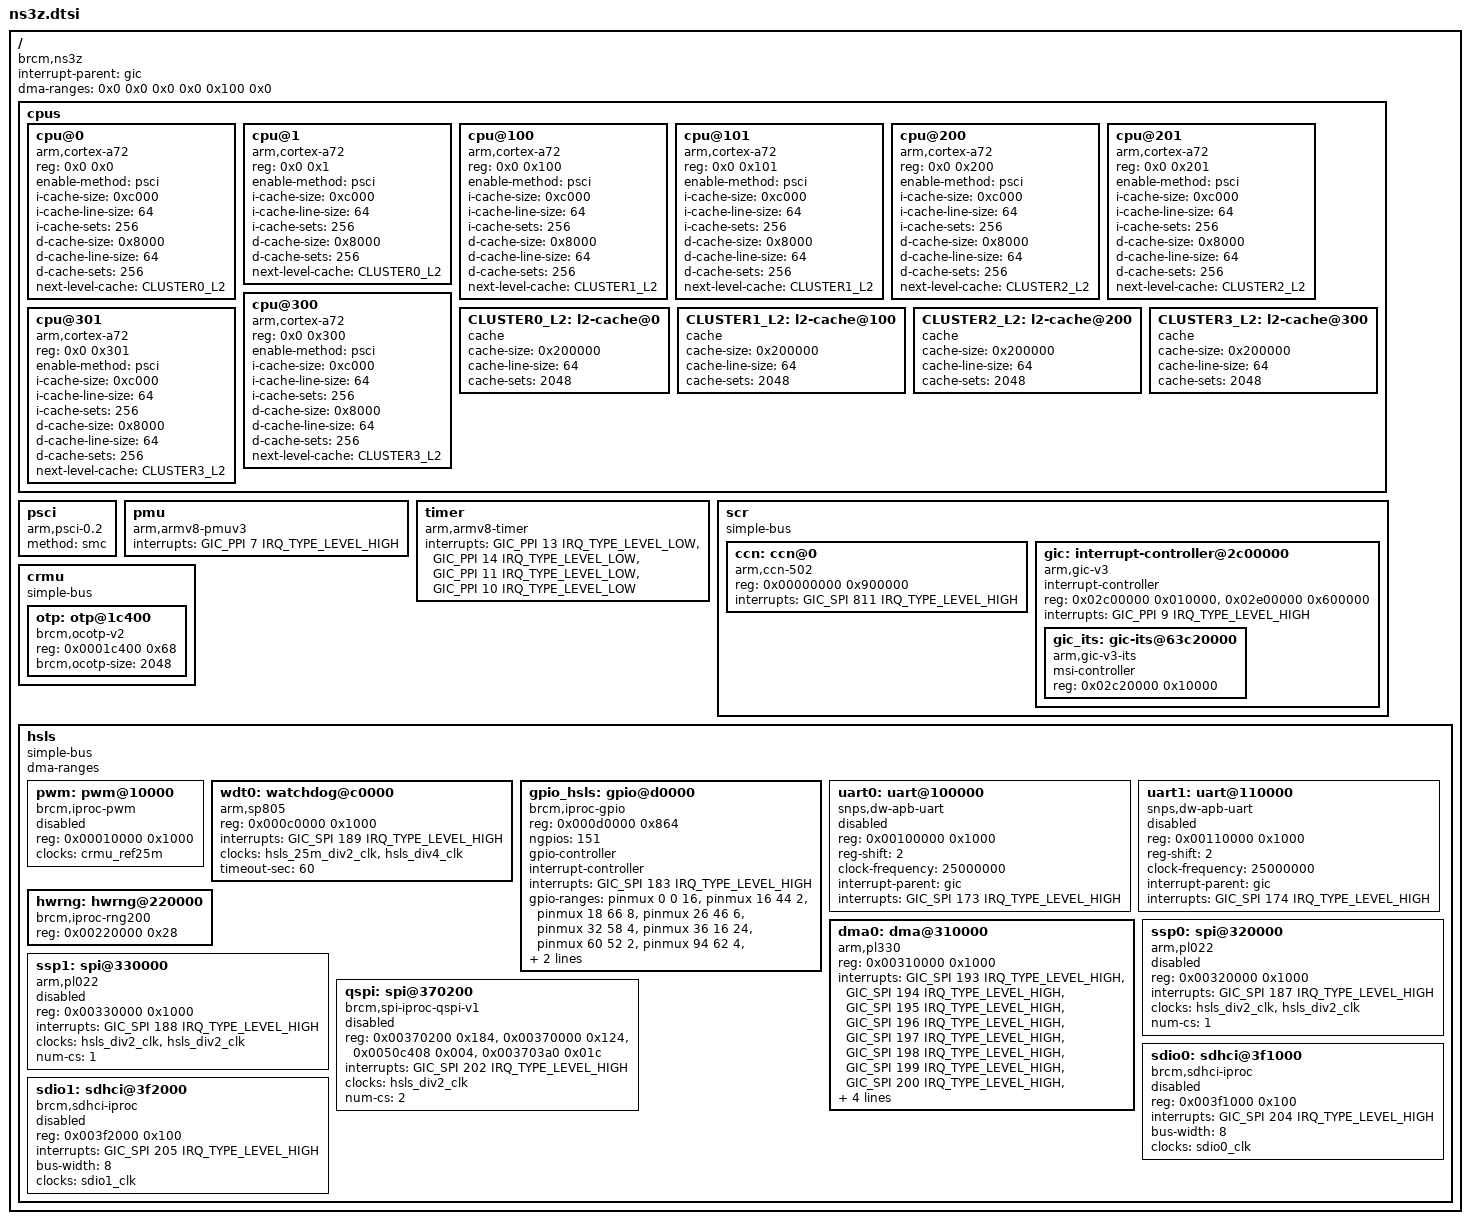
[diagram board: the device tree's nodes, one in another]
// SPDX-License-Identifier: (GPL-2.0 or BSD-3-Clause)
/*
 *  Copyright(c) 2019 Broadcom
 */

#include <dt-bindings/interrupt-controller/arm-gic.h>

/ {
	compatible = "brcm,ns3z";
	interrupt-parent = <&gic>;
	#address-cells = <2>;
	#size-cells = <2>;
	dma-ranges = <0x0 0x0 0x0 0x0 0x100 0x0>;

	cpus {
		#address-cells = <2>;
		#size-cells = <0>;

		cpu@0 {
			device_type = "cpu";
			compatible = "arm,cortex-a72", "arm,armv8";
			reg = <0x0 0x0>;
			enable-method = "psci";
			i-cache-size = <0xc000>;
			i-cache-line-size = <64>;
			i-cache-sets = <256>;
			d-cache-size = <0x8000>;
			d-cache-line-size = <64>;
			d-cache-sets = <256>;
			next-level-cache = <&CLUSTER0_L2>;
		};

		cpu@1 {
			device_type = "cpu";
			compatible = "arm,cortex-a72", "arm,armv8";
			reg = <0x0 0x1>;
			enable-method = "psci";
			i-cache-size = <0xc000>;
			i-cache-line-size = <64>;
			i-cache-sets = <256>;
			d-cache-size = <0x8000>;
			d-cache-sets = <256>;
			next-level-cache = <&CLUSTER0_L2>;
		};

		cpu@100 {
			device_type = "cpu";
			compatible = "arm,cortex-a72", "arm,armv8";
			reg = <0x0 0x100>;
			enable-method = "psci";
			i-cache-size = <0xc000>;
			i-cache-line-size = <64>;
			i-cache-sets = <256>;
			d-cache-size = <0x8000>;
			d-cache-line-size = <64>;
			d-cache-sets = <256>;
			next-level-cache = <&CLUSTER1_L2>;
		};

		cpu@101 {
			device_type = "cpu";
			compatible = "arm,cortex-a72", "arm,armv8";
			reg = <0x0 0x101>;
			enable-method = "psci";
			i-cache-size = <0xc000>;
			i-cache-line-size = <64>;
			i-cache-sets = <256>;
			d-cache-size = <0x8000>;
			d-cache-line-size = <64>;
			d-cache-sets = <256>;
			next-level-cache = <&CLUSTER1_L2>;
		};

		cpu@200 {
			device_type = "cpu";
			compatible = "arm,cortex-a72", "arm,armv8";
			reg = <0x0 0x200>;
			enable-method = "psci";
			i-cache-size = <0xc000>;
			i-cache-line-size = <64>;
			i-cache-sets = <256>;
			d-cache-size = <0x8000>;
			d-cache-line-size = <64>;
			d-cache-sets = <256>;
			next-level-cache = <&CLUSTER2_L2>;
		};

		cpu@201 {
			device_type = "cpu";
			compatible = "arm,cortex-a72", "arm,armv8";
			reg = <0x0 0x201>;
			enable-method = "psci";
			i-cache-size = <0xc000>;
			i-cache-line-size = <64>;
			i-cache-sets = <256>;
			d-cache-size = <0x8000>;
			d-cache-line-size = <64>;
			d-cache-sets = <256>;
			next-level-cache = <&CLUSTER2_L2>;
		};

		cpu@300 {
			device_type = "cpu";
			compatible = "arm,cortex-a72", "arm,armv8";
			reg = <0x0 0x300>;
			enable-method = "psci";
			i-cache-size = <0xc000>;
			i-cache-line-size = <64>;
			i-cache-sets = <256>;
			d-cache-size = <0x8000>;
			d-cache-line-size = <64>;
			d-cache-sets = <256>;
			next-level-cache = <&CLUSTER3_L2>;
		};

		cpu@301 {
			device_type = "cpu";
			compatible = "arm,cortex-a72", "arm,armv8";
			reg = <0x0 0x301>;
			enable-method = "psci";
			i-cache-size = <0xc000>;
			i-cache-line-size = <64>;
			i-cache-sets = <256>;
			d-cache-size = <0x8000>;
			d-cache-line-size = <64>;
			d-cache-sets = <256>;
			next-level-cache = <&CLUSTER3_L2>;
		};

		CLUSTER0_L2: l2-cache@0 {
			compatible = "cache";
			cache-size = <0x200000>;
			cache-line-size = <64>;
			cache-sets = <2048>;
		};

		CLUSTER1_L2: l2-cache@100 {
			compatible = "cache";
			cache-size = <0x200000>;
			cache-line-size = <64>;
			cache-sets = <2048>;
		};

		CLUSTER2_L2: l2-cache@200 {
			compatible = "cache";
			cache-size = <0x200000>;
			cache-line-size = <64>;
			cache-sets = <2048>;
		};

		CLUSTER3_L2: l2-cache@300 {
			compatible = "cache";
			cache-size = <0x200000>;
			cache-line-size = <64>;
			cache-sets = <2048>;
		};
	};

	psci {
		compatible = "arm,psci-0.2";
		method = "smc";
	};

	pmu {
		compatible = "arm,armv8-pmuv3";
		interrupts = <GIC_PPI 7 IRQ_TYPE_LEVEL_HIGH>;
	};

	timer {
		compatible = "arm,armv8-timer";
		interrupts = <GIC_PPI 13 IRQ_TYPE_LEVEL_LOW>,
			     <GIC_PPI 14 IRQ_TYPE_LEVEL_LOW>,
			     <GIC_PPI 11 IRQ_TYPE_LEVEL_LOW>,
			     <GIC_PPI 10 IRQ_TYPE_LEVEL_LOW>;
	};

	scr {
		compatible = "simple-bus";
		#address-cells = <1>;
		#size-cells = <1>;
		ranges = <0x0 0x0 0x61000000 0x05000000>;
		#include "ns3z-clock.dtsi"

		ccn: ccn@0 {
			compatible = "arm,ccn-502";
			reg = <0x00000000 0x900000>;
			interrupts = <GIC_SPI 811 IRQ_TYPE_LEVEL_HIGH>;
		};

		gic: interrupt-controller@2c00000 {
			compatible = "arm,gic-v3";
			#interrupt-cells = <3>;
			#address-cells = <1>;
			#size-cells = <1>;
			ranges;
			interrupt-controller;
			reg = <0x02c00000 0x010000>, /* GICD */
			      <0x02e00000 0x600000>; /* GICR */
			interrupts = <GIC_PPI 9 IRQ_TYPE_LEVEL_HIGH>;

			gic_its: gic-its@63c20000 {
				compatible = "arm,gic-v3-its";
				msi-controller;
				#msi-cells = <1>;
				reg = <0x02c20000 0x10000>;
			};
		};
	};

	crmu: crmu {
		compatible = "simple-bus";
		#address-cells = <1>;
		#size-cells = <1>;
		ranges = <0x0 0x0 0x66400000 0x100000>;

		otp: otp@1c400 {
			compatible = "brcm,ocotp-v2";
			reg = <0x0001c400 0x68>;
			brcm,ocotp-size = <2048>;
			status = "okay";
		};
	};

	hsls {
		compatible = "simple-bus";
		dma-ranges;
		#address-cells = <1>;
		#size-cells = <1>;
		ranges = <0x0 0x0 0x68900000 0x17700000>;

		#include "ns3z-pinctrl.dtsi"

		pwm: pwm@10000 {
			compatible = "brcm,iproc-pwm";
			reg = <0x00010000 0x1000>;
			clocks = <&crmu_ref25m>;
			#pwm-cells = <3>;
			status = "disabled";
		};

		wdt0: watchdog@c0000 {
			compatible = "arm,sp805", "arm,primecell";
			reg = <0x000c0000 0x1000>;
			interrupts = <GIC_SPI 189 IRQ_TYPE_LEVEL_HIGH>;
			clocks = <&hsls_25m_div2_clk>, <&hsls_div4_clk>;
			clock-names = "wdogclk", "apb_pclk";
			timeout-sec = <60>;
		};

		gpio_hsls: gpio@d0000 {
			compatible = "brcm,iproc-gpio";
			reg = <0x000d0000 0x864>;
			ngpios = <151>;
			#gpio-cells = <2>;
			gpio-controller;
			interrupt-controller;
			#interrupt-cells = <2>;
			interrupts = <GIC_SPI 183 IRQ_TYPE_LEVEL_HIGH>;
			gpio-ranges = <&pinmux 0 0 16>,
				      <&pinmux 16 44 2>,
				      <&pinmux 18 66 8>,
				      <&pinmux 26 46 6>,
				      <&pinmux 32 58 4>,
				      <&pinmux 36 16 24>,
				      <&pinmux 60 52 2>,
				      <&pinmux 94 62 4>,
				      <&pinmux 102 74 4>,
				      <&pinmux 141 40 4>,
				      <&pinmux 145 78 6>,
				      <&pinmux 151 54 4>;
		};

		uart0: uart@100000 {
			device_type = "serial";
			compatible = "snps,dw-apb-uart";
			reg = <0x00100000 0x1000>;
			reg-shift = <2>;
			clock-frequency = <25000000>;
			interrupt-parent = <&gic>;
			interrupts = <GIC_SPI 173 IRQ_TYPE_LEVEL_HIGH>;
			status = "disabled";
		};

		uart1: uart@110000 {
			device_type = "serial";
			compatible = "snps,dw-apb-uart";
			reg = <0x00110000 0x1000>;
			reg-shift = <2>;
			clock-frequency = <25000000>;
			interrupt-parent = <&gic>;
			interrupts = <GIC_SPI 174 IRQ_TYPE_LEVEL_HIGH>;
			status = "disabled";
		};

		hwrng: hwrng@220000 {
			compatible = "brcm,iproc-rng200";
			reg = <0x00220000 0x28>;
		};

		dma0: dma@310000 {
			compatible = "arm,pl330", "arm,primecell";
			reg = <0x00310000 0x1000>;
			interrupts = <GIC_SPI 193 IRQ_TYPE_LEVEL_HIGH>,
				     <GIC_SPI 194 IRQ_TYPE_LEVEL_HIGH>,
				     <GIC_SPI 195 IRQ_TYPE_LEVEL_HIGH>,
				     <GIC_SPI 196 IRQ_TYPE_LEVEL_HIGH>,
				     <GIC_SPI 197 IRQ_TYPE_LEVEL_HIGH>,
				     <GIC_SPI 198 IRQ_TYPE_LEVEL_HIGH>,
				     <GIC_SPI 199 IRQ_TYPE_LEVEL_HIGH>,
				     <GIC_SPI 200 IRQ_TYPE_LEVEL_HIGH>,
				     <GIC_SPI 201 IRQ_TYPE_LEVEL_HIGH>;
			#dma-cells = <1>;
			#dma-channels = <8>;
			#dma-requests = <32>;
			clocks = <&hsls_div2_clk>;
			clock-names = "apb_pclk";
		};

		ssp0: spi@320000 {
			compatible = "arm,pl022", "arm,primecell";
			reg = <0x00320000 0x1000>;
			interrupts = <GIC_SPI 187 IRQ_TYPE_LEVEL_HIGH>;
			clocks = <&hsls_div2_clk>, <&hsls_div2_clk>;
			clock-names = "spiclk", "apb_pclk";
			num-cs = <1>;
			#address-cells = <1>;
			#size-cells = <0>;
			status = "disabled";
		};

		ssp1: spi@330000 {
			compatible = "arm,pl022", "arm,primecell";
			reg = <0x00330000 0x1000>;
			interrupts = <GIC_SPI 188 IRQ_TYPE_LEVEL_HIGH>;
			clocks = <&hsls_div2_clk>, <&hsls_div2_clk>;
			clock-names = "spiclk", "apb_pclk";
			num-cs = <1>;
			#address-cells = <1>;
			#size-cells = <0>;
			status = "disabled";
		};

		qspi: spi@370200 {
			compatible = "brcm,spi-iproc-qspi-v1",
				     "brcm,spi-bcm-qspi";
			reg = <0x00370200 0x184>,
			      <0x00370000 0x124>,
			      <0x0050c408 0x004>,
			      <0x003703a0 0x01c>;
			reg-names = "mspi", "bspi", "intr_regs",
				    "intr_status_reg";
			interrupts = <GIC_SPI 202 IRQ_TYPE_LEVEL_HIGH>;
			interrupt-names = "spi_l1_intr";
			clocks = <&hsls_div2_clk>;
			clock-names = "qspi_axi_clk";
			num-cs = <2>;
			#address-cells = <1>;
			#size-cells = <0>;
			status = "disabled";
		};

		sdio0: sdhci@3f1000 {
			compatible = "brcm,sdhci-iproc";
			reg = <0x003f1000 0x100>;
			interrupts = <GIC_SPI 204 IRQ_TYPE_LEVEL_HIGH>;
			bus-width = <8>;
			clocks = <&sdio0_clk>;
			status = "disabled";
		};

		sdio1: sdhci@3f2000 {
			compatible = "brcm,sdhci-iproc";
			reg = <0x003f2000 0x100>;
			interrupts = <GIC_SPI 205 IRQ_TYPE_LEVEL_HIGH>;
			bus-width = <8>;
			clocks = <&sdio1_clk>;
			status = "disabled";
		};

	};

};
